# A31G33x register map
Vendor: VENDOR ABOV Semiconductor Co., Ltd.; Series: A31G33x; File version: 1.0
CPU: CM0+ r0p1, little endian, no MPU, no FPU, VTOR, 2 interrupt priority bits
Registers are 32-bit, read-only, no defined reset value unless marked. A register's access mark holds for its fields unless they carry their own. Offsets are from the block's base; [hi:lo] are bit positions; {n}, {i} and the like mark numbered series; 'fields as' and 'values as' point back to an identical list.

## INTC — Interrupt Controller
Base 0x40001000
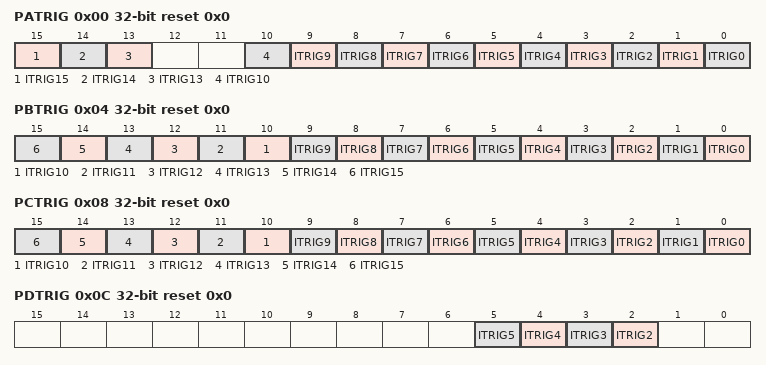
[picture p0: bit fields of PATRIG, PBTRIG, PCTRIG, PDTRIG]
0x00 PATRIG rw reset 0x0 — Port A Interrupt Trigger Selection Register
  [all] fields
    0=Edge trigger interrupt; 1=Level trigger interrupt
  [15] ITRIG15 — Port A Interrupt Trigger Selection 15
  [14] ITRIG14 — Port A Interrupt Trigger Selection 14
  [13] ITRIG13 — Port A Interrupt Trigger Selection 13
  [n] ITRIG{n} (n=0..10) — Port A Interrupt Trigger Selection {n}
0x04 PBTRIG rw reset 0x0 — Port B Interrupt Trigger Selection Register
  [all] fields
    0=Edge trigger interrupt; 1=Level trigger interrupt
  [n] ITRIG{n} (n=0..15) — Port B Interrupt Trigger Selection {n}
0x08 PCTRIG rw reset 0x0 — Port C Interrupt Trigger Selection Register
  [all] fields
    0=Edge trigger interrupt; 1=Level trigger interrupt
  [n] ITRIG{n} (n=0..15) — Port C Interrupt Trigger Selection {n}
0x0C PDTRIG rw reset 0x0 — Port D Interrupt Trigger Selection Register
  [all] fields
    0=Edge trigger interrupt; 1=Level trigger interrupt
  [n] ITRIG{n} (n=2..5) — Port D Interrupt Trigger Selection {n}
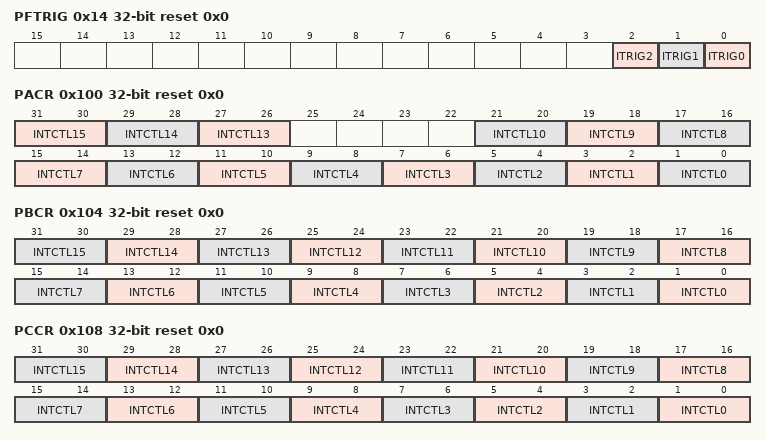
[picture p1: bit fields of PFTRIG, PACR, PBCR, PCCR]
0x14 PFTRIG rw reset 0x0 — Port F Interrupt Trigger Selection Register
  [all] fields
    0=Edge trigger interrupt; 1=Level trigger interrupt
  [2] ITRIG2 — Port F Interrupt Trigger Selection 2
  [1] ITRIG1 — Port F Interrupt Trigger Selection 1
  [0] ITRIG0 — Port F Interrupt Trigger Selection 0
0x100 PACR rw reset 0x0 — Port A Interrupt Control Register
  [all] fields
    0=Disable external interrupt; 1=FallingEdgeLowLevel (Interrupt on falling edge or on low level); 2=RisingEdgeHighLevel (Interrupt on rising edge or on high level); 3=BothEdgeNoLevel (Interrupt on both falling and rising edge, No level interrupt)
  [31:30] INTCTL15 — Port A Interrupt Control 15
  [29:28] INTCTL14 — Port A Interrupt Control 14
  [27:26] INTCTL13 — Port A Interrupt Control 13
  [2n+1:2n] INTCTL{n} (n=0..10) — Port A Interrupt Control {n}
0x104 PBCR rw reset 0x0 — Port B Interrupt Control Register
  [all] fields
    values as the fields of PACR
  [2n+1:2n] INTCTL{n} (n=0..15) — Port B Interrupt Control {n}
0x108 PCCR rw reset 0x0 — Port C Interrupt Control Register
  [all] fields
    values as the fields of PACR
  [2n+1:2n] INTCTL{n} (n=0..15) — Port C Interrupt Control {n}
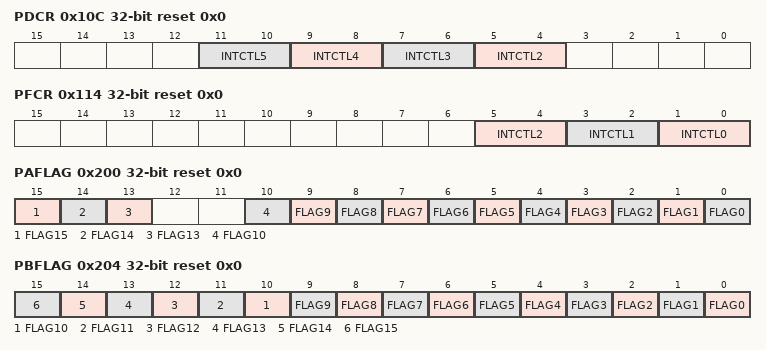
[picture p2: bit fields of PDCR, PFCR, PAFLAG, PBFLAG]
0x10C PDCR rw reset 0x0 — Port D Interrupt Control Register
  [all] fields
    values as the fields of PACR
  [2n+1:2n] INTCTL{n} (n=2..5) — Port D Interrupt Control {n}
0x114 PFCR rw reset 0x0 — Port F Interrupt Control Register
  [all] fields
    values as the fields of PACR
  [5:4] INTCTL2 — Port F Interrupt Control 2
  [3:2] INTCTL1 — Port F Interrupt Control 1
  [1:0] INTCTL0 — Port F Interrupt Control 0
0x200 PAFLAG rw reset 0x0 — Port A Interrupt Flag Register
  [all] fields
    0=No request occurred; 1=Request occurred
  [15] FLAG15 — Port A Interrupt Flag 15
  [14] FLAG14 — Port A Interrupt Flag 14
  [13] FLAG13 — Port A Interrupt Flag 13
  [n] FLAG{n} (n=0..10) — Port A Interrupt Flag {n}
0x204 PBFLAG rw reset 0x0 — Port B Interrupt Flag Register
  [all] fields
    0=No request occurred; 1=Request occurred
  [n] FLAG{n} (n=0..15) — Port B Interrupt Flag {n}
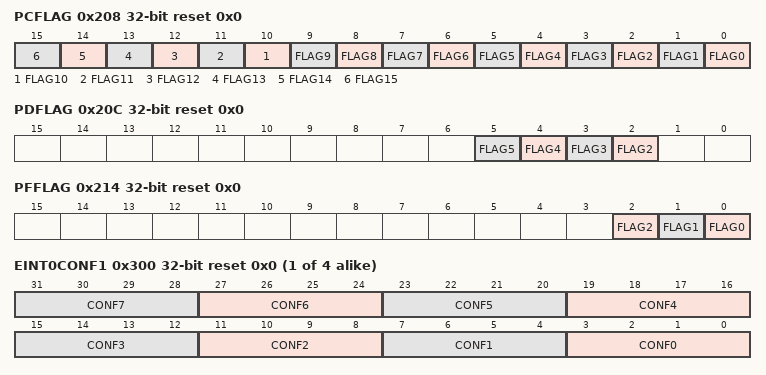
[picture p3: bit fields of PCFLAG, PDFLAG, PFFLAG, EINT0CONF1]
0x208 PCFLAG rw reset 0x0 — Port C Interrupt Flag Register
  [all] fields
    0=No request occurred; 1=Request occurred
  [n] FLAG{n} (n=0..15) — Port C Interrupt Flag {n}
0x20C PDFLAG rw reset 0x0 — Port D Interrupt Flag Register
  [all] fields
    0=No request occurred; 1=Request occurred
  [n] FLAG{n} (n=2..5) — Port D Interrupt Flag {n}
0x214 PFFLAG rw reset 0x0 — Port F Interrupt Flag Register
  [all] fields
    0=No request occurred; 1=Request occurred
  [2] FLAG2 — Port F Interrupt Flag 2
  [1] FLAG1 — Port F Interrupt Flag 1
  [0] FLAG0 — Port F Interrupt Flag 0
{0x300+4i} EINT{i}CONF1 rw reset 0x0 (i=0..3) — External Interrupt {i} Configuration Register 1
  [all] fields
    0=PA (Select PA.); 1=PB (Select PB.); 2=PC (Select PC.); 3=PD (Select PD.); 5=PF (Select PF.)
  [4n+3:4n] CONF{n} (n=0..7) — External Interrupt {i} Configuration {n}
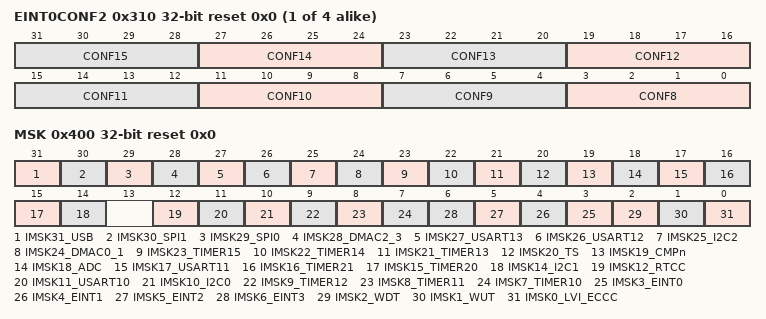
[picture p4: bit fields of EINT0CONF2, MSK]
{0x310+4i} EINT{i}CONF2 rw reset 0x0 (i=0..3) — External Interrupt {i} Configuration Register 2
  [all] fields
    values as the fields of EINT0CONF1
  [4n-29:4n-32] CONF{n} (n=8..15) — External Interrupt {i} Configuration {n}
0x400 MSK rw reset 0x0 — Interrupt Source Mask Register
  [all] fields
    0=Mask Interrupt Source; 1=Unmask Interrupt Source
  [31] IMSK31_USB — Interrupt Source Mask 31 (USB)
  [30] IMSK30_SPI1 — Interrupt Source Mask 30 (SPI1)
  [29] IMSK29_SPI0 — Interrupt Source Mask 29 (SPI0)
  [28] IMSK28_DMAC2_3 — Interrupt Source Mask 28 (DMAC2/3)
  [27] IMSK27_USART13 — Interrupt Source Mask 27 (TIMER13)
  [26] IMSK26_USART12 — Interrupt Source Mask 26 (USART12)
  [25] IMSK25_I2C2 — Interrupt Source Mask 25 (I2C2)
  [24] IMSK24_DMAC0_1 — Interrupt Source Mask 24 (DMAC0/1)
  [23] IMSK23_TIMER15 — Interrupt Source Mask 23 (TIMER15)
  [22] IMSK22_TIMER14 — Interrupt Source Mask 22 (TIMER14)
  [21] IMSK21_TIMER13 — Interrupt Source Mask 21 (TIMER13)
  [20] IMSK20_TS — Interrupt Source Mask 20 (TS)
  [19] IMSK19_CMPn — Interrupt Source Mask 19 (CMPn)
  [18] IMSK18_ADC — Interrupt Source Mask 18 (ADC)
  [17] IMSK17_USART11 — Interrupt Source Mask 17 (USART11)
  [16] IMSK16_TIMER21 — Interrupt Source Mask 16 (TIMER21)
  [15] IMSK15_TIMER20 — Interrupt Source Mask 15 (TIMER20)
  [14] IMSK14_I2C1 — Interrupt Source Mask 14 (I2C1)
  [12] IMSK12_RTCC — Interrupt Source Mask 12 (RTCC)
  [11] IMSK11_USART10 — Interrupt Source Mask 11 (USART10)
  [10] IMSK10_I2C0 — Interrupt Source Mask 10 (I2C0)
  [9] IMSK9_TIMER12 — Interrupt Source Mask 9 (TIMER12)
  [8] IMSK8_TIMER11 — Interrupt Source Mask 8 (TIMER11)
  [7] IMSK7_TIMER10 — Interrupt Source Mask 7 (TIMER10)
  [n] IMSK{n}_EINT{n-3} (n=3..6) — Interrupt Source Mask {n} (EINT{n-3})
  [2] IMSK2_WDT — Interrupt Source Mask 2 (WDT)
  [1] IMSK1_WUT — Interrupt Source Mask 1 (WUT)
  [0] IMSK0_LVI_ECCC — Interrupt Source Mask 0 (LVI/ECCC)
